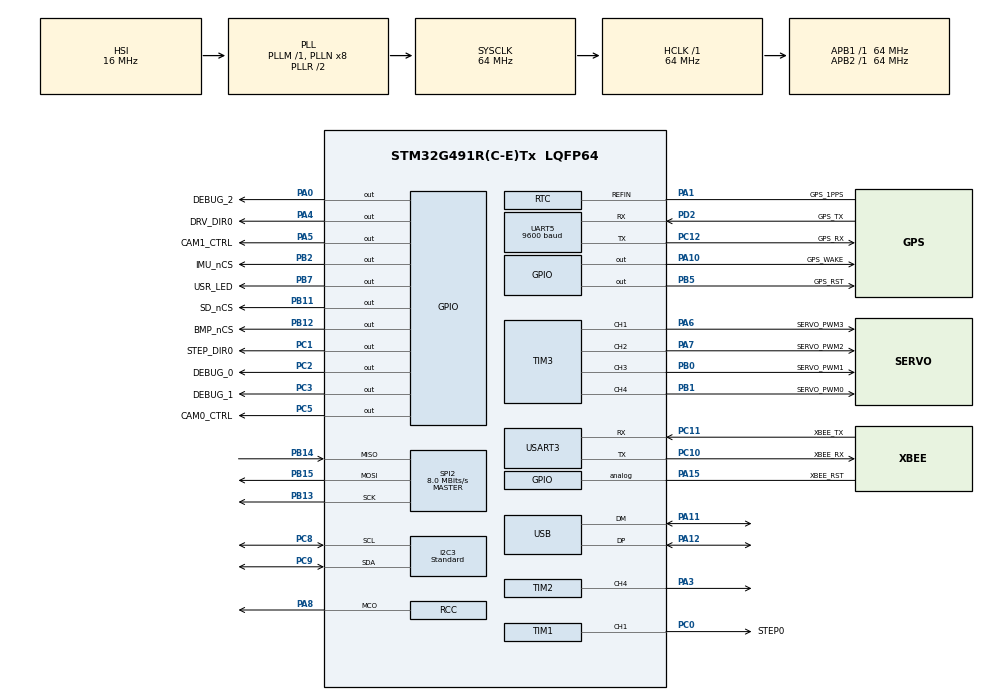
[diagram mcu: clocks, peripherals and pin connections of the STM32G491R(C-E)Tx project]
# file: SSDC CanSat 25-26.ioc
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ADC1.Channel-0\#ChannelRegularConversion=ADC_CHANNEL_VBAT
ADC1.NbrOfConversionFlag=1
ADC1.OffsetNumber-0\#ChannelRegularConversion=ADC_OFFSET_NONE
ADC1.Rank-0\#ChannelRegularConversion=1
ADC1.SamplingTime-0\#ChannelRegularConversion=ADC_SAMPLETIME_2CYCLES_5
ADC1.master=1
Dma.Request0=UART5_RX
Dma.Request1=USART3_RX
Dma.UART5_RX.0.Direction=DMA_PERIPH_TO_MEMORY
Dma.UART5_RX.0.EventEnable=DISABLE
Dma.UART5_RX.0.Instance=DMA1_Channel1
Dma.UART5_RX.0.MemDataAlignment=DMA_MDATAALIGN_BYTE
Dma.UART5_RX.0.MemInc=DMA_MINC_ENABLE
Dma.UART5_RX.0.Mode=DMA_NORMAL
Dma.UART5_RX.0.PeriphDataAlignment=DMA_PDATAALIGN_BYTE
Dma.UART5_RX.0.PeriphInc=DMA_PINC_DISABLE
Dma.UART5_RX.0.Polarity=HAL_DMAMUX_REQ_GEN_RISING
Dma.UART5_RX.0.Priority=DMA_PRIORITY_VERY_HIGH
Dma.UART5_RX.0.RequestNumber=1
Dma.UART5_RX.0.SignalID=NONE
Dma.UART5_RX.0.SyncEnable=DISABLE
Dma.UART5_RX.0.SyncPolarity=HAL_DMAMUX_SYNC_NO_EVENT
Dma.UART5_RX.0.SyncRequestNumber=1
Dma.UART5_RX.0.SyncSignalID=NONE
Dma.USART3_RX.1.Direction=DMA_PERIPH_TO_MEMORY
Dma.USART3_RX.1.EventEnable=DISABLE
Dma.USART3_RX.1.Instance=DMA1_Channel2
Dma.USART3_RX.1.MemDataAlignment=DMA_MDATAALIGN_BYTE
Dma.USART3_RX.1.MemInc=DMA_MINC_ENABLE
Dma.USART3_RX.1.Mode=DMA_NORMAL
Dma.USART3_RX.1.PeriphDataAlignment=DMA_PDATAALIGN_BYTE
Dma.USART3_RX.1.PeriphInc=DMA_PINC_DISABLE
Dma.USART3_RX.1.Polarity=HAL_DMAMUX_REQ_GEN_RISING
Dma.USART3_RX.1.Priority=DMA_PRIORITY_VERY_HIGH
Dma.USART3_RX.1.RequestNumber=1
Dma.USART3_RX.1.SignalID=NONE
Dma.USART3_RX.1.SyncEnable=DISABLE
Dma.USART3_RX.1.SyncPolarity=HAL_DMAMUX_SYNC_NO_EVENT
Dma.USART3_RX.1.SyncRequestNumber=1
Dma.USART3_RX.1.SyncSignalID=NONE
FATFS._FS_LOCK=1
FATFS._FS_REENTRANT=0
FATFS._USE_LFN=0
FATFS._USE_MUTEX=1
FREERTOS.BinarySemaphores01=globalData,Dynamic,NULL,Available
FREERTOS.Tasks01=readSensors,0,600,StartReadSensors,Default,NULL,Dynamic,NULL,NULL;readCommands,0,600,StartReadCommands,Default,NULL,Dynamic,NULL,NULL;sendTelemetry,0,600,StartSendTelemetry,Default,NULL,Dynamic,NULL,NULL;guideNavCtrl,0,600,StartGNC,Default,NULL,Dynamic,NULL,NULL;Init,3,512,StartInit,Default,NULL,Dynamic,NULL,NULL
FREERTOS.configMINIMAL_STACK_SIZE=256
FREERTOS.configTOTAL_HEAP_SIZE=18000
FREERTOS.configUSE_NEWLIB_REENTRANT=1
I2C3.CustomTiming=Disabled
I2C3.I2C_Rise_Time=100
I2C3.I2C_Speed_Mode=I2C_Standard
I2C3.Timing=0x10B17DB5
Mcu.Family=STM32G4
Mcu.Name=STM32G491R(C-E)Tx
Mcu.Package=LQFP64
NVIC.DMA1_Channel1_IRQn=true\:5\:0\:false\:false\:true\:true\:false\:true\:true
NVIC.DMA1_Channel2_IRQn=true\:5\:0\:false\:false\:true\:true\:false\:true\:true
NVIC.PriorityGroup=NVIC_PRIORITYGROUP_4
NVIC.TIM1_UP_TIM16_IRQn=true\:5\:0\:false\:false\:true\:true\:false\:true\:true
NVIC.TIM6_DAC_IRQn=true\:15\:0\:false\:false\:true\:false\:false\:true\:true
NVIC.TimeBase=TIM6_DAC_IRQn
NVIC.TimeBaseIP=TIM6
NVIC.USART3_IRQn=true\:14\:0\:true\:false\:true\:true\:true\:true\:true
NVIC.USB_LP_IRQn=true\:5\:0\:false\:false\:true\:true\:false\:true\:true
PA0.GPIO_Label=DEBUG_2
PA0.Signal=GPIO_Output
PA1.GPIO_Label=GPS_1PPS
PA1.Mode=Reference_Clock_Detection_Activate
PA1.Signal=RTC_REFIN
PA10.GPIO_Label=GPS_WAKE
PA10.Signal=GPIO_Output
PA11.Mode=Device
PA11.Signal=USB_DM
PA12.Mode=Device
PA12.Signal=USB_DP
PA13.GPIO_Label=SWDIO
PA13.Mode=Trace_Asynchronous_SW
PA13.Signal=SYS_JTMS-SWDIO
PA14.GPIO_Label=SWCLK
PA14.Mode=Trace_Asynchronous_SW
PA14.Signal=SYS_JTCK-SWCLK
PA15.GPIO_Label=XBEE_RST
PA15.Signal=GPIO_Analog
PA2.GPIO_Label=CLK_32k
PA2.Mode=Clock-out-LSCO
PA2.Signal=RCC_LSCO
PA3.Signal=S_TIM2_CH4
PA4.GPIO_Label=DRV_DIR0
PA4.Signal=GPIO_Output
PA5.GPIO_Label=CAM1_CTRL
PA5.Signal=GPIO_Output
PA6.GPIO_Label=SERVO_PWM3
PA6.Signal=S_TIM3_CH1
PA7.GPIO_Label=SERVO_PWM2
PA7.Signal=S_TIM3_CH2
PA8.Mode=Clock-out
PA8.Signal=RCC_MCO
PB0.GPIO_Label=SERVO_PWM1
PB0.Signal=S_TIM3_CH3
PB1.GPIO_Label=SERVO_PWM0
PB1.Signal=S_TIM3_CH4
PB11.GPIO_Label=SD_nCS
PB11.Signal=GPIO_Output
PB12.GPIO_Label=BMP_nCS
PB12.Signal=GPIO_Output
PB13.Mode=Full_Duplex_Master
PB13.Signal=SPI2_SCK
PB14.Mode=Full_Duplex_Master
PB14.Signal=SPI2_MISO
PB15.Mode=Full_Duplex_Master
PB15.Signal=SPI2_MOSI
PB2.GPIO_Label=IMU_nCS
PB2.Signal=GPIO_Output
PB3.GPIO_Label=SWO
PB3.Mode=Trace_Asynchronous_SW
PB3.Signal=SYS_JTDO-SWO
PB5.GPIO_Label=GPS_RST
PB5.Signal=GPIO_Output
PB7.GPIO_Label=USR_LED
PB7.Signal=GPIO_Output
PC0.GPIO_Label=STEP0
PC0.Signal=S_TIM1_CH1
PC1.GPIO_Label=STEP_DIR0
PC1.Signal=GPIO_Output
PC10.GPIO_Label=XBEE_RX
PC10.Mode=Asynchronous
PC10.Signal=USART3_TX
PC11.GPIO_Label=XBEE_TX
PC11.Mode=Asynchronous
PC11.Signal=USART3_RX
PC12.GPIO_Label=GPS_RX
PC12.Mode=Asynchronous
PC12.Signal=UART5_TX
PC14-OSC32_IN.GPIO_Label=OSC32_IN
PC14-OSC32_IN.Mode=LSE-External-Oscillator
PC14-OSC32_IN.Signal=RCC_OSC32_IN
PC15-OSC32_OUT.GPIO_Label=OSC32_OUT
PC15-OSC32_OUT.Mode=LSE-External-Oscillator
PC15-OSC32_OUT.Signal=RCC_OSC32_OUT
PC2.GPIO_Label=DEBUG_0
PC2.Signal=GPIO_Output
PC3.GPIO_Label=DEBUG_1
PC3.Signal=GPIO_Output
PC5.GPIO_Label=CAM0_CTRL
PC5.Signal=GPIO_Output
PC8.Mode=I2C
PC8.Signal=I2C3_SCL
PC9.Mode=I2C
PC9.Signal=I2C3_SDA
PD2.GPIO_Label=GPS_TX
PD2.Mode=Asynchronous
PD2.Signal=UART5_RX
ProjectManager.HeapSize=0x400
ProjectManager.StackSize=0x800
ProjectManager.TargetToolchain=STM32CubeIDE
RCC.ADC12Freq_Value=64000000
RCC.ADC345Freq_Value=64000000
RCC.AHBFreq_Value=64000000
RCC.APB1Freq_Value=64000000
RCC.APB1TimFreq_Value=64000000
RCC.APB2Freq_Value=64000000
RCC.APB2TimFreq_Value=64000000
RCC.CortexFreq_Value=64000000
RCC.EXTERNAL_CLOCK_VALUE=12288000
RCC.HCLKFreq_Value=64000000
RCC.HSE_VALUE=8000000
RCC.HSI48_VALUE=48000000
RCC.HSI_VALUE=16000000
RCC.LSCOSource1=RCC_LSCOSOURCE_LSE
RCC.SYSCLKFreq_VALUE=64000000
RCC.SYSCLKSource=RCC_SYSCLKSOURCE_PLLCLK
RCC.VCOOutputFreq_Value=128000000
SH.S_TIM1_CH1.0=TIM1_CH1,PWM Generation1 CH1
SH.S_TIM2_CH4.0=TIM2_CH4,PWM Generation4 CH4
SH.S_TIM3_CH1.0=TIM3_CH1,PWM Generation1 CH1
SH.S_TIM3_CH2.0=TIM3_CH2,PWM Generation2 CH2
SH.S_TIM3_CH3.0=TIM3_CH3,PWM Generation3 CH3
SH.S_TIM3_CH4.0=TIM3_CH4,PWM Generation4 CH4
SPI2.BaudRatePrescaler=SPI_BAUDRATEPRESCALER_8
SPI2.CLKPhase=SPI_PHASE_2EDGE
SPI2.CLKPolarity=SPI_POLARITY_HIGH
SPI2.CalculateBaudRate=8.0 MBits/s
SPI2.DataSize=SPI_DATASIZE_8BIT
SPI2.Direction=SPI_DIRECTION_2LINES
SPI2.Mode=SPI_MODE_MASTER
SPI2.VirtualType=VM_MASTER
TIM1.Channel-PWM\ Generation1\ CH1=TIM_CHANNEL_1
TIM16.Channel=TIM_CHANNEL_1
TIM17.Channel=TIM_CHANNEL_1
TIM2.Channel-PWM\ Generation4\ CH4=TIM_CHANNEL_4
TIM3.Channel-PWM\ Generation3\ CH3=TIM_CHANNEL_3
TIM3.Channel-PWM\ Generation4\ CH4=TIM_CHANNEL_4
UART5.BaudRate=9600
USART3.VirtualMode-Asynchronous=VM_ASYNC
USB_DEVICE.CLASS_NAME_FS=DFU
USB_DEVICE.VirtualMode=Dfu
USB_DEVICE.VirtualModeFS=Dfu_FS
VP_ADC1_TempSens_Input.Mode=IN-TempSens
VP_ADC1_Vbat_Input.Mode=IN-Vbat
VP_ADC1_Vref_Input.Mode=IN-Vrefint
VP_CORDIC_VS_CORDIC.Mode=CORDIC_Activate
VP_FATFS_VS_Generic.Mode=User_defined
VP_FMAC_VS_FMAC.Mode=FMAC_Activate
VP_FREERTOS_VS_CMSIS_V1.Mode=CMSIS_V1
VP_RCC_VS_LSE.Mode=CRS SYNC Source LSE
VP_RNG_VS_RNG.Mode=RNG_Activate
VP_RTC_VS_RTC_Activate.Mode=RTC_Enabled
VP_SYS_VS_DBSignals.Mode=DisableDeadBatterySignals
VP_SYS_VS_tim6.Mode=TIM6
VP_SYS_V_PVD_IN.Mode=Mode_PVD_Int
VP_SYS_V_VREFBUF.Mode=ExternalMode
VP_TIM16_VS_ClockSourceINT.Mode=Enable_Timer
VP_TIM16_VS_no_output1.Mode=PWM Generation1 No Output
VP_TIM17_VS_ClockSourceINT.Mode=Enable_Timer
VP_TIM17_VS_no_output1.Mode=PWM Generation1 No Output
VP_TIM1_VS_ClockSourceINT.Mode=Internal
VP_TIM2_VS_ClockSourceINT.Mode=Internal
VP_TIM3_VS_ClockSourceINT.Mode=Internal
VP_USB_DEVICE_VS_USB_DEVICE_DFU_FS.Mode=DFU_FS
board=custom

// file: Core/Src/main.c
/* USER CODE BEGIN Header */
/**
 ******************************************************************************
 * @file           : main.c
 * @brief          : Main program body
 ******************************************************************************
 * @attention
 *
 * Copyright (c) 2025 STMicroelectronics.
 * All rights reserved.
 *
 * This software is licensed under terms that can be found in the LICENSE file
 * in the root directory of this software component.
 * If no LICENSE file comes with this software, it is provided AS-IS.
 *
 ******************************************************************************
 */
/* USER CODE END Header */
#include "main.h"
#include "cmsis_os.h"
#include "app_fatfs.h"
#include "usb_device.h"

/* USER CODE BEGIN Includes */
#include "../Inc/config.h"
#include "../Inc/global.h"
#include "../Inc/xbee.h"
#include "../Inc/microSD.h"
#include "../Inc/FreeRTOSConfig.h"
#include "../../Drivers/MS5607/MS5607SPI.h"       // Pressure and Temperature Sensor
#include "../../Drivers/ICM42688P/ICM42688PSPI.h" // Accelerometer and Gyro Sensor
#include "../../Drivers/BQ28Z610/BQ28Z610I2C.h"   // Voltage and Current
#include "../../Drivers/STUSB4500LBJR/USB_port.h" // USB PD controller
#include "../../Drivers/TeseoLIV3F/LIV3F.h"         // GPS Module
#include "../../Drivers/SERVO/SERVO.h"      // Servos
#include "../../Middlewares/Third_Party/FreeRTOS/Source/include/task.h"
#include "../Inc/GNC.h"
/* USER CODE END Includes */

/* USER CODE BEGIN PD */

#define BUFFER_SIZE 		256
#define XBEE_MAX_PAYLOAD 	80   // Safe value

#define SERVO_Motor0 4
#define SERVO_Motor1 3
#define SERVO_Motor2 2
#define SERVO_Motor3 1
#define SERVO_Motor4 0

#define EGG_SERVO 		SERVO_Motor0
#define RELEASE_SERVO0 	SERVO_Motor4
#define RELEASE_SERVO1 	SERVO_Motor2
#define GUIDE_SERVO0	SERVO_Motor3
#define GUIDE_SERVO1	SERVO_Motor1
/* USER CODE END PD */

ADC_HandleTypeDef hadc1;

CORDIC_HandleTypeDef hcordic;

FMAC_HandleTypeDef hfmac;

I2C_HandleTypeDef hi2c3;

RNG_HandleTypeDef hrng;

RTC_HandleTypeDef hrtc;

SPI_HandleTypeDef hspi2;

TIM_HandleTypeDef htim1;
TIM_HandleTypeDef htim2;
TIM_HandleTypeDef htim3;
TIM_HandleTypeDef htim16;
TIM_HandleTypeDef htim17;

UART_HandleTypeDef huart5;
UART_HandleTypeDef huart3;
DMA_HandleTypeDef hdma_uart5_rx;
DMA_HandleTypeDef hdma_usart3_rx;

osThreadId readSensorsHandle;
osThreadId readCommandsHandle;
osThreadId sendTelemetryHandle;
osThreadId guideNavCtrlHandle;
osThreadId InitHandle;
osSemaphoreId globalDataHandle;
/* USER CODE BEGIN PV */

uint16_t Timer1, Timer2;
uint8_t gps_dma_buffer[BUFFER_SIZE]   = { 0 };
uint8_t xbee_dma_buffer[BUFFER_SIZE]  = { 0 };
char gps_receive_buffer[BUFFER_SIZE]  = { 0 };
char xbee_receive_buffer[BUFFER_SIZE]  = { 0 };

// At what tick was the last HAL reset.
// Used when we call to update the time.
volatile uint32_t HAL_TICK_OFFSET = 0; // Set when ST is called.

// Flags for GPS and XBEE since they use UART DMA
volatile uint16_t GPS_SIZE 	   		= 0;
volatile uint8_t GPS_READY 	   		= 0;
volatile uint16_t COMMAND_SIZE 		= 0;
volatile uint8_t COMMAND_READY 		= 0;
volatile uint8_t GPS_TIME_ENABLE 	= 0;

GGA_Data_t 		gga_data;
RMC_Data_t 		rmc_data;
PSTMPV_Data_t 	pstmpv_data;

ICM42688P_AccelData ICM42688P_Data = {0};

// GNC Private Variables (PV)
Nav nav 		= {0}; // Initialized in readCommands.
Guidance guid 	= {0}; // no guidance initially, can set this to zero
AutoPilot ap 	= {0}; // same story with the autopilot, can set this to zero
volatile uint8_t CALIBRATE_HEAD_NEEDED = 1;

/* USER CODE END PV */

void SystemClock_Config(void);
static void MX_GPIO_Init(void);
static void MX_DMA_Init(void);
static void MX_RTC_Init(void);
static void MX_SPI2_Init(void);
static void MX_ADC1_Init(void);
static void MX_CORDIC_Init(void);
static void MX_FMAC_Init(void);
static void MX_I2C3_Init(void);
static void MX_RNG_Init(void);
static void MX_UART5_Init(void);
static void MX_USART3_UART_Init(void);
static void MX_TIM3_Init(void);
static void MX_TIM16_Init(void);
static void MX_TIM17_Init(void);
static void MX_TIM1_Init(void);
static void MX_TIM2_Init(void);
void StartReadSensors(void const * argument);
void StartReadCommands(void const * argument);
void StartSendTelemetry(void const * argument);
void StartGNC(void const * argument);
void StartInit(void const * argument);

/* USER CODE BEGIN 0 */

void HAL_UARTEx_RxEventCallback(UART_HandleTypeDef *huart, uint16_t size)
{
  if (huart->Instance == UART5)
  {
    if (!GPS_READY)
    {
		memcpy(gps_receive_buffer, gps_dma_buffer, size);
		GPS_SIZE = size;
		GPS_READY = 1;
		memset(gps_dma_buffer, 0, size);
    }

    if (__HAL_UART_GET_FLAG(&huart5, UART_FLAG_ORE)) {
      __HAL_UART_CLEAR_FLAG(&huart5, UART_CLEAR_OREF);
    }

    HAL_UARTEx_ReceiveToIdle_DMA(huart, gps_dma_buffer, BUFFER_SIZE);
    __HAL_DMA_DISABLE_IT(huart->hdmarx, DMA_IT_HT);
  }

  else if (huart->Instance == USART3)
  {
    if (!COMMAND_READY)
    {
    	memcpy(xbee_receive_buffer, xbee_dma_buffer, size);
    	COMMAND_SIZE = size;
		COMMAND_READY = 1;
		memset(xbee_dma_buffer, 0, size);

    }

    if (__HAL_UART_GET_FLAG(&huart3, UART_FLAG_ORE)) {
    	__HAL_UART_CLEAR_FLAG(&huart3, UART_CLEAR_OREF);
    }

    HAL_UARTEx_ReceiveToIdle_DMA(huart, xbee_dma_buffer, sizeof(xbee_dma_buffer));
    __HAL_DMA_DISABLE_IT(huart->hdmarx, DMA_IT_HT);
  }
  else
  {
    // FIXME : Change this for a DBG LED in the new code
	  HAL_GPIO_TogglePin(DEBUG_1_GPIO_Port, DEBUG_1_Pin);
  }
}

void HAL_UARTEx_ErrorCallback(UART_HandleTypeDef *huart) {
	while(1) {
		// 1 quick 2 slow to show a UART error
		// HAL_GPIO_WritePin(DEBUG_0_GPIO_Port, DEBUG_0_Pin, GPIO_PIN_RESET);
		HAL_Delay(100);
		// HAL_GPIO_WritePin(DEBUG_0_GPIO_Port, DEBUG_0_Pin, GPIO_PIN_RESET);
		HAL_Delay(100);
		// HAL_GPIO_WritePin(DEBUG_0_GPIO_Port, DEBUG_0_Pin, GPIO_PIN_RESET);
		HAL_Delay(200);
		// HAL_GPIO_WritePin(DEBUG_0_GPIO_Port, DEBUG_0_Pin, GPIO_PIN_RESET);
		HAL_Delay(200);
		// HAL_GPIO_WritePin(DEBUG_0_GPIO_Port, DEBUG_0_Pin, GPIO_PIN_RESET);
		HAL_Delay(200);
		// HAL_GPIO_WritePin(DEBUG_0_GPIO_Port, DEBUG_0_Pin, GPIO_PIN_RESET);
		HAL_Delay(200);
	}
}

/* USER CODE END 0 */

int main(void)
{

  /* MCU Configuration--------------------------------------------------------*/

  /* Reset of all peripherals, Initializes the Flash interface and the Systick. */
  HAL_Init();

  /* Configure the system clock */
  SystemClock_Config();

  /* Initialize all configured peripherals */
  MX_GPIO_Init();
  MX_DMA_Init();
  MX_RTC_Init();
  MX_SPI2_Init();
  MX_ADC1_Init();
  MX_CORDIC_Init();
  MX_FMAC_Init();
  MX_I2C3_Init();
  MX_RNG_Init();
  MX_UART5_Init();
  MX_USART3_UART_Init();
  MX_TIM3_Init();
  MX_TIM16_Init();
  MX_TIM17_Init();
  if (MX_FATFS_Init() != APP_OK) {
    Error_Handler();
  }
  MX_TIM1_Init();
  MX_TIM2_Init();
  /* USER CODE BEGIN 2 */

  init_mission_data();
  // Disable ALL chip selects
  HAL_GPIO_WritePin(IMU_nCS_GPIO_Port, IMU_nCS_Pin, GPIO_PIN_SET);
  HAL_GPIO_WritePin(BMP_nCS_GPIO_Port, BMP_nCS_Pin, GPIO_PIN_SET);
  HAL_GPIO_WritePin(SD_nCS_GPIO_Port, SD_nCS_Pin, GPIO_PIN_SET);

  // Hold GPS in reset (LOW)
  HAL_GPIO_WritePin(GPS_RST_GPIO_Port, GPS_RST_Pin, GPIO_PIN_RESET);
  HAL_Delay(100);

  // Fully reset UART5 peripheral
  __HAL_RCC_UART5_FORCE_RESET();
  __HAL_RCC_UART5_RELEASE_RESET();
  MX_UART5_Init();   // reinitialize UART

  // Clear all flags
  __HAL_UART_CLEAR_OREFLAG(&huart5);
  __HAL_UART_CLEAR_FEFLAG(&huart5);
  __HAL_UART_CLEAR_NEFLAG(&huart5);
  __HAL_UART_CLEAR_PEFLAG(&huart5);

  // Fully reset UART3 peripheral
  __HAL_RCC_USART3_FORCE_RESET();
  __HAL_RCC_USART3_RELEASE_RESET();
  MX_USART3_UART_Init();   // reinitialize UART

  // Clear all flags
  __HAL_UART_CLEAR_OREFLAG(&huart3);
  __HAL_UART_CLEAR_FEFLAG(&huart3);
  __HAL_UART_CLEAR_NEFLAG(&huart3);
  __HAL_UART_CLEAR_PEFLAG(&huart3);

  // Now release GPS reset
  HAL_GPIO_WritePin(GPS_RST_GPIO_Port, GPS_RST_Pin, GPIO_PIN_SET);
  HAL_Delay(5000);

  teseo_INIT(&huart5);

  HAL_GPIO_WritePin(XBEE_RST_GPIO_Port, XBEE_RST_Pin, GPIO_PIN_SET);

  // Initalize the tempearture and pressure sensor (MS5607)
  MS5607_Init(&hspi2, BMP_nCS_GPIO_Port, BMP_nCS_Pin);

  ICM42688P_init(&hspi2, IMU_nCS_GPIO_Port, IMU_nCS_Pin);

  // Enable DMA call backs
  // UART 5
  // Check if ORE flag is set, which can happen if data is present on UART RX line
  if (__HAL_UART_GET_FLAG(&huart5, UART_FLAG_ORE)) {
    __HAL_UART_CLEAR_FLAG(&huart5, UART_CLEAR_OREF);
  }
  // receive until idle, then trigger interrupt
  HAL_UARTEx_ReceiveToIdle_DMA(&huart5, gps_dma_buffer, BUFFER_SIZE); // receive until idle, then trigger interrupt
  __HAL_DMA_DISABLE_IT(huart5.hdmarx, DMA_IT_HT); // Disables "Half Transfer" interrupt

  // USART 3
  // Check if ORE flag is set, which can happen if data is present on UART RX line
  if (__HAL_UART_GET_FLAG(&huart3, UART_FLAG_ORE)) {
    __HAL_UART_CLEAR_FLAG(&huart3, UART_CLEAR_OREF);
  }
  // receive until idle, then trigger interrupt
  HAL_UARTEx_ReceiveToIdle_DMA(&huart3, xbee_dma_buffer, sizeof(xbee_dma_buffer)); // receive until idle, then trigger interrupt
  __HAL_DMA_DISABLE_IT(huart3.hdmarx, DMA_IT_HT); // Disables "Half Transfer" interrupt

  /* USER CODE END 2 */

  /* Create the semaphores(s) */
  /* definition and creation of globalData */
  osSemaphoreDef(globalData);
  globalDataHandle = osSemaphoreCreate(osSemaphore(globalData), 1);

  /* Create the thread(s) */
  /* definition and creation of readSensors */
  osThreadDef(readSensors, StartReadSensors, osPriorityNormal, 0, 600);
  readSensorsHandle = osThreadCreate(osThread(readSensors), NULL);

  /* definition and creation of readCommands */
  osThreadDef(readCommands, StartReadCommands, osPriorityNormal, 0, 600);
  readCommandsHandle = osThreadCreate(osThread(readCommands), NULL);

  /* definition and creation of sendTelemetry */
  osThreadDef(sendTelemetry, StartSendTelemetry, osPriorityNormal, 0, 600);
  sendTelemetryHandle = osThreadCreate(osThread(sendTelemetry), NULL);

  /* definition and creation of guideNavCtrl */
  osThreadDef(guideNavCtrl, StartGNC, osPriorityNormal, 0, 600);
  guideNavCtrlHandle = osThreadCreate(osThread(guideNavCtrl), NULL);

  /* definition and creation of Init */
  osThreadDef(Init, StartInit, osPriorityRealtime, 0, 512);
  InitHandle = osThreadCreate(osThread(Init), NULL);

  /* Start scheduler */
  osKernelStart();

  /* We should never get here as control is now taken by the scheduler */

  /* Infinite loop */
  while (1)
  {

  }
}

void SystemClock_Config(void)
{
  RCC_OscInitTypeDef RCC_OscInitStruct = {0};
  RCC_ClkInitTypeDef RCC_ClkInitStruct = {0};
  RCC_CRSInitTypeDef pInit = {0};

  /** Configure the main internal regulator output voltage
  */
  HAL_PWREx_ControlVoltageScaling(PWR_REGULATOR_VOLTAGE_SCALE1);

  /** Configure LSE Drive Capability
  */
  HAL_PWR_EnableBkUpAccess();
  __HAL_RCC_LSEDRIVE_CONFIG(RCC_LSEDRIVE_LOW);

  /** Initializes the RCC Oscillators according to the specified parameters
  * in the RCC_OscInitTypeDef structure.
  */
  RCC_OscInitStruct.OscillatorType = RCC_OSCILLATORTYPE_HSI|RCC_OSCILLATORTYPE_HSI48
                              |RCC_OSCILLATORTYPE_LSI|RCC_OSCILLATORTYPE_LSE;
  RCC_OscInitStruct.LSEState = RCC_LSE_ON;
  RCC_OscInitStruct.HSIState = RCC_HSI_ON;
  RCC_OscInitStruct.HSICalibrationValue = RCC_HSICALIBRATION_DEFAULT;
  RCC_OscInitStruct.LSIState = RCC_LSI_ON;
  RCC_OscInitStruct.HSI48State = RCC_HSI48_ON;
  RCC_OscInitStruct.PLL.PLLState = RCC_PLL_ON;
  RCC_OscInitStruct.PLL.PLLSource = RCC_PLLSOURCE_HSI;
  RCC_OscInitStruct.PLL.PLLM = RCC_PLLM_DIV1;
  RCC_OscInitStruct.PLL.PLLN = 8;
  RCC_OscInitStruct.PLL.PLLP = RCC_PLLP_DIV2;
  RCC_OscInitStruct.PLL.PLLQ = RCC_PLLQ_DIV2;
  RCC_OscInitStruct.PLL.PLLR = RCC_PLLR_DIV2;
  if (HAL_RCC_OscConfig(&RCC_OscInitStruct) != HAL_OK)
  {
    Error_Handler();
  }

  /** Initializes the CPU, AHB and APB buses clocks
  */
  RCC_ClkInitStruct.ClockType = RCC_CLOCKTYPE_HCLK|RCC_CLOCKTYPE_SYSCLK
                              |RCC_CLOCKTYPE_PCLK1|RCC_CLOCKTYPE_PCLK2;
  RCC_ClkInitStruct.SYSCLKSource = RCC_SYSCLKSOURCE_PLLCLK;
  RCC_ClkInitStruct.AHBCLKDivider = RCC_SYSCLK_DIV1;
  RCC_ClkInitStruct.APB1CLKDivider = RCC_HCLK_DIV1;
  RCC_ClkInitStruct.APB2CLKDivider = RCC_HCLK_DIV1;

  if (HAL_RCC_ClockConfig(&RCC_ClkInitStruct, FLASH_LATENCY_2) != HAL_OK)
  {
    Error_Handler();
  }
  HAL_RCC_MCOConfig(RCC_MCO1, RCC_MCO1SOURCE_HSI, RCC_MCODIV_1);
  HAL_RCCEx_EnableLSCO(RCC_LSCOSOURCE_LSE);

  /** Enable the SYSCFG APB clock
  */
  __HAL_RCC_CRS_CLK_ENABLE();

  /** Configures CRS
  */
  pInit.Prescaler = RCC_CRS_SYNC_DIV1;
  pInit.Source = RCC_CRS_SYNC_SOURCE_LSE;
  pInit.Polarity = RCC_CRS_SYNC_POLARITY_RISING;
  pInit.ReloadValue = __HAL_RCC_CRS_RELOADVALUE_CALCULATE(48000000,32768);
  pInit.ErrorLimitValue = 34;
  pInit.HSI48CalibrationValue = 32;

  HAL_RCCEx_CRSConfig(&pInit);
}

static void MX_ADC1_Init(void)
{

  ADC_MultiModeTypeDef multimode = {0};
  ADC_ChannelConfTypeDef sConfig = {0};

  /** Common config
  */
  hadc1.Instance = ADC1;
  hadc1.Init.ClockPrescaler = ADC_CLOCK_SYNC_PCLK_DIV2;
  hadc1.Init.Resolution = ADC_RESOLUTION_12B;
  hadc1.Init.DataAlign = ADC_DATAALIGN_RIGHT;
  hadc1.Init.GainCompensation = 0;
  hadc1.Init.ScanConvMode = ADC_SCAN_DISABLE;
  hadc1.Init.EOCSelection = ADC_EOC_SINGLE_CONV;
  hadc1.Init.LowPowerAutoWait = DISABLE;
  hadc1.Init.ContinuousConvMode = DISABLE;
  hadc1.Init.NbrOfConversion = 1;
  hadc1.Init.DiscontinuousConvMode = DISABLE;
  hadc1.Init.ExternalTrigConv = ADC_SOFTWARE_START;
  hadc1.Init.ExternalTrigConvEdge = ADC_EXTERNALTRIGCONVEDGE_NONE;
  hadc1.Init.DMAContinuousRequests = DISABLE;
  hadc1.Init.Overrun = ADC_OVR_DATA_PRESERVED;
  hadc1.Init.OversamplingMode = DISABLE;
  if (HAL_ADC_Init(&hadc1) != HAL_OK)
  {
    Error_Handler();
  }

  /** Configure the ADC multi-mode
  */
  multimode.Mode = ADC_MODE_INDEPENDENT;
  if (HAL_ADCEx_MultiModeConfigChannel(&hadc1, &multimode) != HAL_OK)
  {
    Error_Handler();
  }

  /** Configure Regular Channel
  */
  sConfig.Channel = ADC_CHANNEL_VBAT;
  sConfig.Rank = ADC_REGULAR_RANK_1;
  sConfig.SamplingTime = ADC_SAMPLETIME_2CYCLES_5;
  sConfig.SingleDiff = ADC_SINGLE_ENDED;
  sConfig.OffsetNumber = ADC_OFFSET_NONE;
  sConfig.Offset = 0;
  if (HAL_ADC_ConfigChannel(&hadc1, &sConfig) != HAL_OK)
  {
    Error_Handler();
  }

}

static void MX_CORDIC_Init(void)
{

  hcordic.Instance = CORDIC;
  if (HAL_CORDIC_Init(&hcordic) != HAL_OK)
  {
    Error_Handler();
  }

}

static void MX_FMAC_Init(void)
{

  hfmac.Instance = FMAC;
  if (HAL_FMAC_Init(&hfmac) != HAL_OK)
  {
    Error_Handler();
  }

}

static void MX_I2C3_Init(void)
{

  hi2c3.Instance = I2C3;
  hi2c3.Init.Timing = 0x10B17DB5;
  hi2c3.Init.OwnAddress1 = 0;
  hi2c3.Init.AddressingMode = I2C_ADDRESSINGMODE_7BIT;
  hi2c3.Init.DualAddressMode = I2C_DUALADDRESS_DISABLE;
  hi2c3.Init.OwnAddress2 = 0;
  hi2c3.Init.OwnAddress2Masks = I2C_OA2_NOMASK;
  hi2c3.Init.GeneralCallMode = I2C_GENERALCALL_DISABLE;
  hi2c3.Init.NoStretchMode = I2C_NOSTRETCH_DISABLE;
  if (HAL_I2C_Init(&hi2c3) != HAL_OK)
  {
    Error_Handler();
  }

  /** Configure Analogue filter
  */
  if (HAL_I2CEx_ConfigAnalogFilter(&hi2c3, I2C_ANALOGFILTER_ENABLE) != HAL_OK)
  {
    Error_Handler();
  }

  /** Configure Digital filter
  */
  if (HAL_I2CEx_ConfigDigitalFilter(&hi2c3, 0) != HAL_OK)
  {
    Error_Handler();
  }

}

static void MX_RNG_Init(void)
{

  hrng.Instance = RNG;
  hrng.Init.ClockErrorDetection = RNG_CED_ENABLE;
  if (HAL_RNG_Init(&hrng) != HAL_OK)
  {
    Error_Handler();
  }

}

static void MX_RTC_Init(void)
{

  /** Initialize RTC Only
  */
  hrtc.Instance = RTC;
  hrtc.Init.HourFormat = RTC_HOURFORMAT_24;
  hrtc.Init.AsynchPrediv = 127;
  hrtc.Init.SynchPrediv = 255;
  hrtc.Init.OutPut = RTC_OUTPUT_DISABLE;
  hrtc.Init.OutPutRemap = RTC_OUTPUT_REMAP_NONE;
  hrtc.Init.OutPutPolarity = RTC_OUTPUT_POLARITY_HIGH;
  hrtc.Init.OutPutType = RTC_OUTPUT_TYPE_OPENDRAIN;
  hrtc.Init.OutPutPullUp = RTC_OUTPUT_PULLUP_NONE;
  if (HAL_RTC_Init(&hrtc) != HAL_OK)
  {
    Error_Handler();
  }

  /** Enable the reference Clock input
  */
  if (HAL_RTCEx_SetRefClock(&hrtc) != HAL_OK)
  {
    Error_Handler();
  }

}

static void MX_SPI2_Init(void)
{

  /* SPI2 parameter configuration*/
  hspi2.Instance = SPI2;
  hspi2.Init.Mode = SPI_MODE_MASTER;
  hspi2.Init.Direction = SPI_DIRECTION_2LINES;
  hspi2.Init.DataSize = SPI_DATASIZE_8BIT;
  hspi2.Init.CLKPolarity = SPI_POLARITY_HIGH;
  hspi2.Init.CLKPhase = SPI_PHASE_2EDGE;
  hspi2.Init.NSS = SPI_NSS_SOFT;
  hspi2.Init.BaudRatePrescaler = SPI_BAUDRATEPRESCALER_8;
  hspi2.Init.FirstBit = SPI_FIRSTBIT_MSB;
  hspi2.Init.TIMode = SPI_TIMODE_DISABLE;
  hspi2.Init.CRCCalculation = SPI_CRCCALCULATION_DISABLE;
  hspi2.Init.CRCPolynomial = 7;
  hspi2.Init.CRCLength = SPI_CRC_LENGTH_DATASIZE;
  hspi2.Init.NSSPMode = SPI_NSS_PULSE_DISABLE;
  if (HAL_SPI_Init(&hspi2) != HAL_OK)
  {
    Error_Handler();
  }

}

static void MX_TIM1_Init(void)
{

  TIM_ClockConfigTypeDef sClockSourceConfig = {0};
  TIM_MasterConfigTypeDef sMasterConfig = {0};
  TIM_OC_InitTypeDef sConfigOC = {0};
  TIM_BreakDeadTimeConfigTypeDef sBreakDeadTimeConfig = {0};

  htim1.Instance = TIM1;
  htim1.Init.Prescaler = 0;
  htim1.Init.CounterMode = TIM_COUNTERMODE_UP;
  htim1.Init.Period = 65535;
  htim1.Init.ClockDivision = TIM_CLOCKDIVISION_DIV1;
  htim1.Init.RepetitionCounter = 0;
  htim1.Init.AutoReloadPreload = TIM_AUTORELOAD_PRELOAD_DISABLE;
  if (HAL_TIM_Base_Init(&htim1) != HAL_OK)
  {
    Error_Handler();
  }
  sClockSourceConfig.ClockSource = TIM_CLOCKSOURCE_INTERNAL;
  if (HAL_TIM_ConfigClockSource(&htim1, &sClockSourceConfig) != HAL_OK)
  {
    Error_Handler();
  }
  if (HAL_TIM_PWM_Init(&htim1) != HAL_OK)
  {
    Error_Handler();
  }
  sMasterConfig.MasterOutputTrigger = TIM_TRGO_RESET;
  sMasterConfig.MasterOutputTrigger2 = TIM_TRGO2_RESET;
  sMasterConfig.MasterSlaveMode = TIM_MASTERSLAVEMODE_DISABLE;
  if (HAL_TIMEx_MasterConfigSynchronization(&htim1, &sMasterConfig) != HAL_OK)
  {
    Error_Handler();
  }
  sConfigOC.OCMode = TIM_OCMODE_PWM1;
  sConfigOC.Pulse = 0;
  sConfigOC.OCPolarity = TIM_OCPOLARITY_HIGH;
  sConfigOC.OCNPolarity = TIM_OCNPOLARITY_HIGH;
  sConfigOC.OCFastMode = TIM_OCFAST_DISABLE;
  sConfigOC.OCIdleState = TIM_OCIDLESTATE_RESET;
  sConfigOC.OCNIdleState = TIM_OCNIDLESTATE_RESET;
  if (HAL_TIM_PWM_ConfigChannel(&htim1, &sConfigOC, TIM_CHANNEL_1) != HAL_OK)
  {
    Error_Handler();
  }
  sBreakDeadTimeConfig.OffStateRunMode = TIM_OSSR_DISABLE;
  sBreakDeadTimeConfig.OffStateIDLEMode = TIM_OSSI_DISABLE;
  sBreakDeadTimeConfig.LockLevel = TIM_LOCKLEVEL_OFF;
  sBreakDeadTimeConfig.DeadTime = 0;
  sBreakDeadTimeConfig.BreakState = TIM_BREAK_DISABLE;
  sBreakDeadTimeConfig.BreakPolarity = TIM_BREAKPOLARITY_HIGH;
  sBreakDeadTimeConfig.BreakFilter = 0;
  sBreakDeadTimeConfig.BreakAFMode = TIM_BREAK_AFMODE_INPUT;
  sBreakDeadTimeConfig.Break2State = TIM_BREAK2_DISABLE;
  sBreakDeadTimeConfig.Break2Polarity = TIM_BREAK2POLARITY_HIGH;
  sBreakDeadTimeConfig.Break2Filter = 0;
  sBreakDeadTimeConfig.Break2AFMode = TIM_BREAK_AFMODE_INPUT;
  sBreakDeadTimeConfig.AutomaticOutput = TIM_AUTOMATICOUTPUT_DISABLE;
  if (HAL_TIMEx_ConfigBreakDeadTime(&htim1, &sBreakDeadTimeConfig) != HAL_OK)
  {
    Error_Handler();
  }
  HAL_TIM_MspPostInit(&htim1);

}

static void MX_TIM2_Init(void)
{

  TIM_ClockConfigTypeDef sClockSourceConfig = {0};
  TIM_MasterConfigTypeDef sMasterConfig = {0};
  TIM_OC_InitTypeDef sConfigOC = {0};

  htim2.Instance = TIM2;
  htim2.Init.Prescaler = 0;
  htim2.Init.CounterMode = TIM_COUNTERMODE_UP;
  htim2.Init.Period = 4294967295;
  htim2.Init.ClockDivision = TIM_CLOCKDIVISION_DIV1;
  htim2.Init.AutoReloadPreload = TIM_AUTORELOAD_PRELOAD_DISABLE;
  if (HAL_TIM_Base_Init(&htim2) != HAL_OK)
  {
    Error_Handler();
  }
  sClockSourceConfig.ClockSource = TIM_CLOCKSOURCE_INTERNAL;
  if (HAL_TIM_ConfigClockSource(&htim2, &sClockSourceConfig) != HAL_OK)
  {
    Error_Handler();
  }
  if (HAL_TIM_PWM_Init(&htim2) != HAL_OK)
  {
    Error_Handler();
  }
  sMasterConfig.MasterOutputTrigger = TIM_TRGO_RESET;
  sMasterConfig.MasterSlaveMode = TIM_MASTERSLAVEMODE_DISABLE;
  if (HAL_TIMEx_MasterConfigSynchronization(&htim2, &sMasterConfig) != HAL_OK)
  {
    Error_Handler();
  }
  sConfigOC.OCMode = TIM_OCMODE_PWM1;
  sConfigOC.Pulse = 0;
  sConfigOC.OCPolarity = TIM_OCPOLARITY_HIGH;
  sConfigOC.OCFastMode = TIM_OCFAST_DISABLE;
  if (HAL_TIM_PWM_ConfigChannel(&htim2, &sConfigOC, TIM_CHANNEL_4) != HAL_OK)
  {
    Error_Handler();
  }
  HAL_TIM_MspPostInit(&htim2);

}

static void MX_TIM3_Init(void)
{

  TIM_ClockConfigTypeDef sClockSourceConfig = {0};
  TIM_MasterConfigTypeDef sMasterConfig = {0};
  TIM_OC_InitTypeDef sConfigOC = {0};

  htim3.Instance = TIM3;
  htim3.Init.Prescaler = 0;
  htim3.Init.CounterMode = TIM_COUNTERMODE_UP;
  htim3.Init.Period = 65535;
  htim3.Init.ClockDivision = TIM_CLOCKDIVISION_DIV1;
  htim3.Init.AutoReloadPreload = TIM_AUTORELOAD_PRELOAD_DISABLE;
  if (HAL_TIM_Base_Init(&htim3) != HAL_OK)
  {
    Error_Handler();
  }
  sClockSourceConfig.ClockSource = TIM_CLOCKSOURCE_INTERNAL;
  if (HAL_TIM_ConfigClockSource(&htim3, &sClockSourceConfig) != HAL_OK)
  {
    Error_Handler();
  }
  if (HAL_TIM_PWM_Init(&htim3) != HAL_OK)
  {
    Error_Handler();
  }
  sMasterConfig.MasterOutputTrigger = TIM_TRGO_RESET;
  sMasterConfig.MasterSlaveMode = TIM_MASTERSLAVEMODE_DISABLE;
  if (HAL_TIMEx_MasterConfigSynchronization(&htim3, &sMasterConfig) != HAL_OK)
  {
    Error_Handler();
  }
  sConfigOC.OCMode = TIM_OCMODE_PWM1;
  sConfigOC.Pulse = 0;
  sConfigOC.OCPolarity = TIM_OCPOLARITY_HIGH;
  sConfigOC.OCFastMode = TIM_OCFAST_DISABLE;
  if (HAL_TIM_PWM_ConfigChannel(&htim3, &sConfigOC, TIM_CHANNEL_1) != HAL_OK)
  {
    Error_Handler();
  }
  if (HAL_TIM_PWM_ConfigChannel(&htim3, &sConfigOC, TIM_CHANNEL_2) != HAL_OK)
  {
    Error_Handler();
  }
  if (HAL_TIM_PWM_ConfigChannel(&htim3, &sConfigOC, TIM_CHANNEL_3) != HAL_OK)
  {
    Error_Handler();
  }
  if (HAL_TIM_PWM_ConfigChannel(&htim3, &sConfigOC, TIM_CHANNEL_4) != HAL_OK)
  {
    Error_Handler();
  }
  HAL_TIM_MspPostInit(&htim3);

}

static void MX_TIM16_Init(void)
{

  TIM_OC_InitTypeDef sConfigOC = {0};
  TIM_BreakDeadTimeConfigTypeDef sBreakDeadTimeConfig = {0};

  htim16.Instance = TIM16;
  htim16.Init.Prescaler = 0;
  htim16.Init.CounterMode = TIM_COUNTERMODE_UP;
  htim16.Init.Period = 65535;
  htim16.Init.ClockDivision = TIM_CLOCKDIVISION_DIV1;
  htim16.Init.RepetitionCounter = 0;
  htim16.Init.AutoReloadPreload = TIM_AUTORELOAD_PRELOAD_DISABLE;
  if (HAL_TIM_Base_Init(&htim16) != HAL_OK)
  {
    Error_Handler();
  }
  if (HAL_TIM_PWM_Init(&htim16) != HAL_OK)
  {
    Error_Handler();
  }
  sConfigOC.OCMode = TIM_OCMODE_PWM1;
  sConfigOC.Pulse = 0;
  sConfigOC.OCPolarity = TIM_OCPOLARITY_HIGH;
  sConfigOC.OCNPolarity = TIM_OCNPOLARITY_HIGH;
  sConfigOC.OCFastMode = TIM_OCFAST_DISABLE;
  sConfigOC.OCIdleState = TIM_OCIDLESTATE_RESET;
  sConfigOC.OCNIdleState = TIM_OCNIDLESTATE_RESET;
  if (HAL_TIM_PWM_ConfigChannel(&htim16, &sConfigOC, TIM_CHANNEL_1) != HAL_OK)
  {
    Error_Handler();
  }
  sBreakDeadTimeConfig.OffStateRunMode = TIM_OSSR_DISABLE;
  sBreakDeadTimeConfig.OffStateIDLEMode = TIM_OSSI_DISABLE;
  sBreakDeadTimeConfig.LockLevel = TIM_LOCKLEVEL_OFF;
  sBreakDeadTimeConfig.DeadTime = 0;
  sBreakDeadTimeConfig.BreakState = TIM_BREAK_DISABLE;
  sBreakDeadTimeConfig.BreakPolarity = TIM_BREAKPOLARITY_HIGH;
  sBreakDeadTimeConfig.BreakFilter = 0;
  sBreakDeadTimeConfig.AutomaticOutput = TIM_AUTOMATICOUTPUT_DISABLE;
  if (HAL_TIMEx_ConfigBreakDeadTime(&htim16, &sBreakDeadTimeConfig) != HAL_OK)
  {
    Error_Handler();
  }

}

static void MX_TIM17_Init(void)
{

  TIM_OC_InitTypeDef sConfigOC = {0};
  TIM_BreakDeadTimeConfigTypeDef sBreakDeadTimeConfig = {0};

  htim17.Instance = TIM17;
  htim17.Init.Prescaler = 0;
  htim17.Init.CounterMode = TIM_COUNTERMODE_UP;
  htim17.Init.Period = 65535;
  htim17.Init.ClockDivision = TIM_CLOCKDIVISION_DIV1;
  htim17.Init.RepetitionCounter = 0;
  htim17.Init.AutoReloadPreload = TIM_AUTORELOAD_PRELOAD_DISABLE;
  if (HAL_TIM_Base_Init(&htim17) != HAL_OK)
  {
    Error_Handler();
  }
  if (HAL_TIM_PWM_Init(&htim17) != HAL_OK)
  {
    Error_Handler();
  }
  sConfigOC.OCMode = TIM_OCMODE_PWM1;
  sConfigOC.Pulse = 0;
  sConfigOC.OCPolarity = TIM_OCPOLARITY_HIGH;
  sConfigOC.OCNPolarity = TIM_OCNPOLARITY_HIGH;
  sConfigOC.OCFastMode = TIM_OCFAST_DISABLE;
  sConfigOC.OCIdleState = TIM_OCIDLESTATE_RESET;
  sConfigOC.OCNIdleState = TIM_OCNIDLESTATE_RESET;
  if (HAL_TIM_PWM_ConfigChannel(&htim17, &sConfigOC, TIM_CHANNEL_1) != HAL_OK)
  {
    Error_Handler();
  }
  sBreakDeadTimeConfig.OffStateRunMode = TIM_OSSR_DISABLE;
  sBreakDeadTimeConfig.OffStateIDLEMode = TIM_OSSI_DISABLE;
  sBreakDeadTimeConfig.LockLevel = TIM_LOCKLEVEL_OFF;
  sBreakDeadTimeConfig.DeadTime = 0;
  sBreakDeadTimeConfig.BreakState = TIM_BREAK_DISABLE;
  sBreakDeadTimeConfig.BreakPolarity = TIM_BREAKPOLARITY_HIGH;
  sBreakDeadTimeConfig.BreakFilter = 0;
  sBreakDeadTimeConfig.AutomaticOutput = TIM_AUTOMATICOUTPUT_DISABLE;
  if (HAL_TIMEx_ConfigBreakDeadTime(&htim17, &sBreakDeadTimeConfig) != HAL_OK)
  {
    Error_Handler();
  }

}

static void MX_UART5_Init(void)
{

  huart5.Instance = UART5;
  huart5.Init.BaudRate = 9600;
  huart5.Init.WordLength = UART_WORDLENGTH_8B;
  huart5.Init.StopBits = UART_STOPBITS_1;
  huart5.Init.Parity = UART_PARITY_NONE;
  huart5.Init.Mode = UART_MODE_TX_RX;
  huart5.Init.HwFlowCtl = UART_HWCONTROL_NONE;
  huart5.Init.OverSampling = UART_OVERSAMPLING_16;
  huart5.Init.OneBitSampling = UART_ONE_BIT_SAMPLE_DISABLE;
  huart5.Init.ClockPrescaler = UART_PRESCALER_DIV1;
  huart5.AdvancedInit.AdvFeatureInit = UART_ADVFEATURE_NO_INIT;
  if (HAL_UART_Init(&huart5) != HAL_OK)
  {
    Error_Handler();
  }
  if (HAL_UARTEx_SetTxFifoThreshold(&huart5, UART_TXFIFO_THRESHOLD_1_8) != HAL_OK)
  {
    Error_Handler();
  }
  if (HAL_UARTEx_SetRxFifoThreshold(&huart5, UART_RXFIFO_THRESHOLD_1_8) != HAL_OK)
  {
    Error_Handler();
  }
  if (HAL_UARTEx_DisableFifoMode(&huart5) != HAL_OK)
  {
    Error_Handler();
  }

}

static void MX_USART3_UART_Init(void)
{

  huart3.Instance = USART3;
  huart3.Init.BaudRate = 115200;
  huart3.Init.WordLength = UART_WORDLENGTH_8B;
  huart3.Init.StopBits = UART_STOPBITS_1;
  huart3.Init.Parity = UART_PARITY_NONE;
  huart3.Init.Mode = UART_MODE_TX_RX;
  huart3.Init.HwFlowCtl = UART_HWCONTROL_NONE;
  huart3.Init.OverSampling = UART_OVERSAMPLING_16;
  huart3.Init.OneBitSampling = UART_ONE_BIT_SAMPLE_DISABLE;
  huart3.Init.ClockPrescaler = UART_PRESCALER_DIV1;
  huart3.AdvancedInit.AdvFeatureInit = UART_ADVFEATURE_NO_INIT;
  if (HAL_UART_Init(&huart3) != HAL_OK)
  {
    Error_Handler();
  }
  if (HAL_UARTEx_SetTxFifoThreshold(&huart3, UART_TXFIFO_THRESHOLD_1_8) != HAL_OK)
  {
    Error_Handler();
  }
  if (HAL_UARTEx_SetRxFifoThreshold(&huart3, UART_RXFIFO_THRESHOLD_1_8) != HAL_OK)
  {
    Error_Handler();
  }
  if (HAL_UARTEx_DisableFifoMode(&huart3) != HAL_OK)
  {
    Error_Handler();
  }

}

static void MX_DMA_Init(void)
{

  /* DMA controller clock enable */
  __HAL_RCC_DMAMUX1_CLK_ENABLE();
  __HAL_RCC_DMA1_CLK_ENABLE();

  /* DMA interrupt init */
  /* DMA1_Channel1_IRQn interrupt configuration */
  HAL_NVIC_SetPriority(DMA1_Channel1_IRQn, 5, 0);
  HAL_NVIC_EnableIRQ(DMA1_Channel1_IRQn);
  /* DMA1_Channel2_IRQn interrupt configuration */
  HAL_NVIC_SetPriority(DMA1_Channel2_IRQn, 5, 0);
  HAL_NVIC_EnableIRQ(DMA1_Channel2_IRQn);

}

static void MX_GPIO_Init(void)
{
  GPIO_InitTypeDef GPIO_InitStruct = {0};

  /* GPIO Ports Clock Enable */
  __HAL_RCC_GPIOC_CLK_ENABLE();
  __HAL_RCC_GPIOA_CLK_ENABLE();
  __HAL_RCC_GPIOB_CLK_ENABLE();
  __HAL_RCC_GPIOD_CLK_ENABLE();

  /*Configure GPIO pin Output Level */
  HAL_GPIO_WritePin(GPIOC, STEP_DIR0_Pin|DEBUG_0_Pin|DEBUG_1_Pin|CAM0_CTRL_Pin, GPIO_PIN_RESET);

  /*Configure GPIO pin Output Level */
  HAL_GPIO_WritePin(GPIOA, DEBUG_2_Pin|DRV_DIR0_Pin|CAM1_CTRL_Pin|GPS_WAKE_Pin, GPIO_PIN_RESET);

  /*Configure GPIO pin Output Level */
  HAL_GPIO_WritePin(GPIOB, IMU_nCS_Pin|SD_nCS_Pin|BMP_nCS_Pin|GPS_RST_Pin
                          |USR_LED_Pin, GPIO_PIN_RESET);

  /*Configure GPIO pins : STEP_DIR0_Pin DEBUG_0_Pin DEBUG_1_Pin CAM0_CTRL_Pin */
  GPIO_InitStruct.Pin = STEP_DIR0_Pin|DEBUG_0_Pin|DEBUG_1_Pin|CAM0_CTRL_Pin;
  GPIO_InitStruct.Mode = GPIO_MODE_OUTPUT_PP;
  GPIO_InitStruct.Pull = GPIO_NOPULL;
  GPIO_InitStruct.Speed = GPIO_SPEED_FREQ_LOW;
  HAL_GPIO_Init(GPIOC, &GPIO_InitStruct);

  /*Configure GPIO pins : DEBUG_2_Pin DRV_DIR0_Pin CAM1_CTRL_Pin GPS_WAKE_Pin */
  GPIO_InitStruct.Pin = DEBUG_2_Pin|DRV_DIR0_Pin|CAM1_CTRL_Pin|GPS_WAKE_Pin;
  GPIO_InitStruct.Mode = GPIO_MODE_OUTPUT_PP;
  GPIO_InitStruct.Pull = GPIO_NOPULL;
  GPIO_InitStruct.Speed = GPIO_SPEED_FREQ_LOW;
  HAL_GPIO_Init(GPIOA, &GPIO_InitStruct);

  /*Configure GPIO pins : CLK_32k_Pin XBEE_RST_Pin */
  GPIO_InitStruct.Pin = CLK_32k_Pin|XBEE_RST_Pin;
  GPIO_InitStruct.Mode = GPIO_MODE_ANALOG;
  GPIO_InitStruct.Pull = GPIO_NOPULL;
  HAL_GPIO_Init(GPIOA, &GPIO_InitStruct);

  /*Configure GPIO pins : IMU_nCS_Pin SD_nCS_Pin BMP_nCS_Pin GPS_RST_Pin
                           USR_LED_Pin */
  GPIO_InitStruct.Pin = IMU_nCS_Pin|SD_nCS_Pin|BMP_nCS_Pin|GPS_RST_Pin
                          |USR_LED_Pin;
  GPIO_InitStruct.Mode = GPIO_MODE_OUTPUT_PP;
  GPIO_InitStruct.Pull = GPIO_NOPULL;
  GPIO_InitStruct.Speed = GPIO_SPEED_FREQ_LOW;
  HAL_GPIO_Init(GPIOB, &GPIO_InitStruct);

  /*Configure GPIO pin : PA8 */
  GPIO_InitStruct.Pin = GPIO_PIN_8;
  GPIO_InitStruct.Mode = GPIO_MODE_AF_PP;
  GPIO_InitStruct.Pull = GPIO_NOPULL;
  GPIO_InitStruct.Speed = GPIO_SPEED_FREQ_LOW;
  GPIO_InitStruct.Alternate = GPIO_AF0_MCO;
  HAL_GPIO_Init(GPIOA, &GPIO_InitStruct);

}

/* USER CODE BEGIN 4 */
void vApplicationTickHook(void){
	if(Timer1 > 0)
		Timer1--;
	if(Timer2 > 0)
		Timer2--;
}

// This is a call back in case a thread has a stack overflow.
// pcTaskName is the name of the offending task
void vApplicationStackOverflowHook(TaskHandle_t xTask, char *pcTaskName)
{
    (void)xTask;
    (void)pcTaskName;
    // Forces a breakpoint in the debugger
    __BKPT(0);
    for (;;);
}

// Incase there is an error with a Malloc somewhere
void vApplicationMallocFailedHook(void)
{
    // Fires if pvPortMalloc fails — useful to catch heap exhaustion

	// Forces a breakpoint in the debugger
    __BKPT(0);
    for (;;);
}

/* USER CODE END 4 */

void StartReadSensors(void const * argument)
{
  /* init code for USB_Device */
  MX_USB_Device_Init();
  /* USER CODE BEGIN 5 */
  osStatus stat = osErrorOS;

  char testing_data[200];

  /* Infinite loop */
  for (;;)
  {
	stat = osSemaphoreWait(globalDataHandle, 100);
	if (stat != osOK) {
	  osThreadYield();
	  continue;
	}
    // #1 PRIORITY: make sure mutex unlocks no matter what!!!!

    // -> if a HIGHER priority task attempts to access a locked resource,
    // the LOCKING thread assumes the priority of the resource trying to
    // take it

    /*
     * global_mission_data.MODE, global_mission_data.CMD_ECHO,
     * and global_mission_data.PACKET_COUNT
     * is dealt with in readCommands.
     */

    MS5607Readings MS5607_Data = MS5607ReadValues();
    // TODO : This should probably just use the flag simulation_enable
    if (global_mission_data.MODE == 'F')
    { // In Flight Mode
      global_mission_data.PRESSURE = MS5607_Data.pressure_kPa;
    }
    else
    { // In Simulation Mode
     global_mission_data.PRESSURE = simulated_pressure;
    }

    global_mission_data.TEMPERATURE = MS5607_Data.temperature_C;

    global_mission_data.ALTITUDE = calculateAltitude(global_mission_data.PRESSURE) - global_mission_data.ALTITUDE_OFFSET;

    determineState(&nav);

    // ICM42688P_AccelData ICM42688P_Data = ICM42688P_read_data();
    ICM42688P_read_data(&ICM42688P_Data);
    global_mission_data.GYRO_R = ICM42688P_Data.gyro_r;
    global_mission_data.GYRO_P = ICM42688P_Data.gyro_p;
    global_mission_data.GYRO_Y = ICM42688P_Data.gyro_y;

    global_mission_data.ACCEL_X = ICM42688P_Data.accel_x;
    global_mission_data.ACCEL_Y = ICM42688P_Data.accel_y;
    global_mission_data.ACCEL_Z = ICM42688P_Data.accel_z;

    global_mission_data.ACCEL_R = ICM42688P_Data.accel_r;
    global_mission_data.ACCEL_P = ICM42688P_Data.accel_p;
    global_mission_data.ACCEL_YAW = ICM42688P_Data.accel_yaw;

 //   struct bmm350_mag_temp_data mag_data;
 //   BMM350_read_mag_data(&bmm350, &mag_data);

     uint16_t voltage = 0;
     HAL_StatusTypeDef status = BQ28Z610_ReadVoltage(&hi2c3, &voltage);
     if (status == HAL_OK) {
         global_mission_data.VOLTAGE = (float)voltage / 1000;
     }

     int16_t current = 0;
     status = BQ28Z610_ReadCurrent(&hi2c3, &current);
     if (status == HAL_OK)
     {
     	global_mission_data.CURRENT = (float)current / 1000;
     }

    //New code
    if (GPS_READY)
    {
        // From my understanding: When the DMA interrupt occurs, we will copy the message from the DMA buffer
        // into the gps_receive_buffer. From there, we can then pass the receive buffer with the message into parse_gga
        int result = parse_gps_buffer(gps_receive_buffer, &gga_data, &rmc_data, &pstmpv_data);
        GPS_READY = 0;

        //result is 1 on success
        if (result == 1)
        {
 //           HAL_GPIO_TogglePin(DEBUG_0_GPIO_Port, DEBUG_0_Pin);
            global_mission_data.GPS_LATITUDE = gga_data.latitude;
            global_mission_data.GPS_LONGITUDE = gga_data.longitude;
            global_mission_data.GPS_ALTITUDE = gga_data.altitude;
            global_mission_data.GPS_SATS = gga_data.num_satellites;

            strcpy(global_mission_data.GPS_TIME, gga_data.gps_time);
        }
        else if (result == 2)
        {
     	   global_mission_data.GPS_LATITUDE = rmc_data.latitude;
     	   global_mission_data.GPS_LONGITUDE = rmc_data.longitude;

     	   strcpy(global_mission_data.GPS_TIME, rmc_data.gps_time);
        }
        else
        {
     	   HAL_GPIO_TogglePin(DEBUG_2_GPIO_Port, DEBUG_2_Pin);
        }
    }

    if(calibrating) {

        cal_sum += global_mission_data.PRESSURE;
        cal_count++;

        if(cal_count >= 10) {
            float pressure_avg = cal_sum / cal_count;
            global_mission_data.ALTITUDE_OFFSET = calculateAltitude(pressure_avg);

     	   calibrating = 0;
     	   is_calibrated = 1;
        }

	   // TODO: Initialize nav for GNC.
	   //MAIN INITIALIZATION - run once to initialize Nav struct
	           //1) initialize gyro,accel,mag offsets at launch pad
	           //2) read from sensors and run init_Navigation()
	               //EXAMPLE: Nav nav = init_Navigation(data, gga, PSTMPV, GPS_ready);
	               //Guidance guid = {0}; //can make guidance blank until we enter control loop
	           //3) need something that will start the main loop when glider outside container, can we use descent acceleration?
	               /*
	               The accelerometer, though noisy, should measure nearly +1g when the glider reaches terminal velocity.
	               So we can use a conditional that checks ICM42688P accel_z (or whichever axis is pointing vertical) and
	               see when it's close to zero it may be best to do this over an average to avoid fast spikes in accelerometer
	               values affecting when the main loop is started. We will have to coordinate transform this into the NED frame
	               and I can work on getting this done ASAP unless we already have something we can use for this.
	               */
	   //EXAMPLE: MAIN INITIALIZATION - REPLACE NECESSARY ELEMENTS WITH SENSOR STRUCT FIELDS
	   //So for example, gps[3] takes in gga struct latitude, longitude, and altitude (or global struct)

	   //float gps[3] = {global_mission_data.GPS_LATITUDE, global_mission_data.GPS_LONGITUDE, global_mission_data.GPS_ALTITUDE};
	   //float accel[3][1] = {{global_mission_data.ACCEL_X},{global_mission_data.ACCEL_Y},{global_mission_data.ACCEL_Z}}; //acceleration from the accelerometer (g) (XYZ)
	   //float gyro[3][1] = {{global_mission_data.GYRO_R},{global_mission_data.GYRO_P},{global_mission_data.GYRO_Y}}; // Gyro (RPY)

	   //nav = init_Navigation(gps, accel, gyro); //initialize the navigation states

       if (cal_count == 1) {
		   nav = init_Navigation((float[3]){global_mission_data.GPS_LATITUDE, global_mission_data.GPS_LONGITUDE, global_mission_data.GPS_ALTITUDE},
				   (float[3][1]){{global_mission_data.ACCEL_X},{global_mission_data.ACCEL_Y},{global_mission_data.ACCEL_Z}},
				   (float[3][1]){{global_mission_data.GYRO_R},{global_mission_data.GYRO_P},{global_mission_data.GYRO_Y}});
       }
   }

    if (global_flags.mec_egg_release) {
    	SERVO_MoveTo_180(SERVO_Motor0, 0);
    }

//    RTC_TimeTypeDef sTime = {0};
//    // Needed to unlock time registers
//    RTC_DateTypeDef sDate = {0};
//
//    if (HAL_RTC_GetTime(&hrtc, &sTime, RTC_FORMAT_BIN) != HAL_OK)
//    {
//      Error_Handler();
//    }
//
//    // Needed to unlock time registers
//    if (HAL_RTC_GetDate(&hrtc, &sDate, RTC_FORMAT_BIN) != HAL_OK)
//    {
//      Error_Handler();
//    }

//	snprintf(global_mission_data.MISSION_TIME, 9, "XX:XX:XX");
//    snprintf(global_mission_data.MISSION_TIME, 9, "%02d:%02d:%02d",
//             sTime.Hours, sTime.Minutes, sTime.Seconds);

    /*
     * Get Voltage and Current from Magnetometer
     */

    /*
     * Get GPS information from GPS
     */

    // Relinquish access to the global_mission_data struct

//    SERVO_Sweep_180(SERVO_Motor0);

    osSemaphoreRelease(globalDataHandle);

    osDelay(100);
  }
  /* USER CODE END 5 */
}

void StartReadCommands(void const * argument)
{
  /* USER CODE BEGIN StartReadCommands */
	osStatus stat = osErrorOS;

	char rx_string[30];
    for (;;)
    {

        if (!COMMAND_READY) {
            osThreadYield();
            continue;
        }

        // The point of this loop is to find the start delimeter in the DMA buffer.
        // The DMA system will occasionally start with garbage data, this ensures
        //   that it doesn't drop a message for something as stupid as that.
        uint8_t offset = 0;
        for (; offset < 50; offset++) {
       		if (xbee_receive_buffer[offset] == 0x7E) {
        		break;
        	}
        }

        xbee_status_t status = xbee_decode_tx_request(&xbee_receive_buffer[offset], (COMMAND_SIZE-offset), &rx_string[0], sizeof(rx_string), NULL);
        if (status != XBEE_OK) {
            COMMAND_READY = 0;
            continue;
        }

        stat = osSemaphoreWait(globalDataHandle, 100);
        if (stat != osOK) {
            osThreadYield();
            continue; // Semaphore is either unavailable or inputs are wrong
        }
        // HAL_GPIO_TogglePin(DEBUG_0_GPIO_Port, DEBUG_0_Pin);

        if (strncmp(rx_string, "CMD,1075,CX,ON", 14) == 0)
        {
            // set command echo in the global mission struct
            char c_echo[] = "CXON";
            strcpy(global_mission_data.CMD_ECHO, c_echo);
            global_flags.telemetry_enable = 1;
        }
        // CX OFF command -> stop transmitting telemetry packets
        else if (strncmp(rx_string, "CMD,1075,CX,OFF", 15) == 0)
        {
            // set command echo
            char c_echo[] = "CXOFF";
            strcpy(global_mission_data.CMD_ECHO, c_echo);
            global_flags.telemetry_enable = 0;
        }
        // ST command -> set mission time
        else if (strncmp(rx_string, "CMD,1075,ST,", 12) == 0)
        {
            // parse the timestamp to set to
            char arg[9];
            char *time_str = rx_string + 12;
            strncpy(arg, time_str, 9);

            // removed this code because GPS is screwed
            // if a manual timestamp has been input...
            HAL_TICK_OFFSET = HAL_GetTick();
            if (strlen(arg) == 8)
            {
            	// set mission time
                char *str_end;
                strncpy(global_mission_data.MISSION_TIME, time_str, 9);
                string_to_time(&global_mission_data.MISSION_TIME[0], &global_mission_data.MISSION_TIME_ms);
            }
            // read time from GPS
            else if (strncmp(time_str, "GPS", 3) == 0)
            {
            	global_mission_data.MISSION_TIME_ms = rmc_data.time_ms;
            }
            else
            {
            // if the string is not 8 characters long, set it to "00:00:00"
            	strcpy(global_mission_data.MISSION_TIME, "00:00:00");
                string_to_time(&global_mission_data.MISSION_TIME[0], &global_mission_data.MISSION_TIME_ms);
            }

            // set command echo
            char c_echo[] = "ST";
            strcpy(global_mission_data.CMD_ECHO, c_echo);
        }
        // SIM ENABLE command -> allow simulation mode to be activated
        else if (strncmp(rx_string, "CMD,1075,SIM,ENABLE", 19) == 0)
        {
            // set command echo
            char c_echo[] = "SIMENABLE";
            strcpy(global_mission_data.CMD_ECHO, c_echo);
            global_flags.simulation_pre = 1;
        }
        // SIM ACTIVATE command -> turn simulation mode on
        else if (strncmp(rx_string, "CMD,1075,SIM,ACTIVATE", 21) == 0)
        {
            // check that simulation mode has been activated
            if (global_flags.simulation_pre == 1)
            {
                // make first simulated pressure value match actual value
                simulated_pressure = global_mission_data.PRESSURE;
                // set command echo
                char c_echo[] = "SIMACT";
                strcpy(global_mission_data.CMD_ECHO, c_echo);
                memcpy(&global_mission_data.MODE, "S", 1);
            }
            else{
            	char c_echo[] = "SIMACT_REJ";
                strcpy(global_mission_data.CMD_ECHO, c_echo);
            }
        }
        // SIM DISABLE command -> turn simulation mode off
        else if (strncmp(rx_string, "CMD,1075,SIM,DISABLE", 20) == 0)
        {
            // set command echo
            char c_echo[] = "SIMDIS";
            strcpy(global_mission_data.CMD_ECHO, c_echo);
            global_flags.simulation_pre = 0;
            memcpy(&global_mission_data.MODE, "F", 1);
        }
        // SIMP command -> add simulated pressure data
        else if (strncmp(rx_string, "CMD,1075,SIMP,", 14) == 0)
        {
            // parse inputed pressure data
            // char *pressure_str = rx_string + 14;
            // char *str_end;
        	simulated_pressure = atof(rx_string + 14) / 1000.0;
            // if (str_end == pressure_str || *str_end != '\0')
            // it wasn't a valid number
            // set simulated pressure to parsed value

            // set command echo
            char c_echo[] = "SIMP";
            strcpy(global_mission_data.CMD_ECHO, c_echo);
        }
        // CAL command -> calibrate altitude
        else if (strncmp(rx_string, "CMD,1075,CAL", 12) == 0)
        {
            // set command echo
            char c_echo[] = "CAL";
            char new_state[]= "LAUNCH_PAD";

            calibrating = 1;
            cal_sum = 0;
            cal_count = 0;

            strcpy(global_mission_data.STATE, new_state);
            strcpy(global_mission_data.CMD_ECHO, c_echo);
        }
        // MEC WIRE ON command -> actuate (servos?)
        else if (strncmp(rx_string, "CMD,1075,MEC,WIRE,ON", 20) == 0)
        {
        // activate MEC command
        }
        // MEC WIRE OFF command -> stop actuations
        else if (strncmp(rx_string, "CMD,1075,MEC,WIRE,OFF", 21) == 0)
        {
        // turn off MEC command (servos for GNC?)
        }
		// Servo #0
        else if (strncmp(rx_string, "CMD,1075,MEC,SERVO0,", 20) == 0)
		{
		  float angle = atof(rx_string + 20);
		  SERVO_MoveTo_180(SERVO_Motor0, angle);
		}
		// Servo #1
        else if (strncmp(rx_string, "CMD,1075,MEC,SERVO1,", 20) == 0)
		{
		  float angle = atof(rx_string + 20);
		  SERVO_MoveTo_180(SERVO_Motor1, angle);
		}
		// Servo #2
        else if (strncmp(rx_string, "CMD,1075,MEC,SERVO2,", 20) == 0)
		{
		  float angle = atof(rx_string + 20);
		  SERVO_MoveTo_180(SERVO_Motor2, angle);
		}
		// Servo #3
        else if (strncmp(rx_string, "CMD,1075,MEC,SERVO3,", 20) == 0)
		{
		  float angle = atof(rx_string + 20);
		  SERVO_MoveTo_180(SERVO_Motor3, angle);
		}
		// Servo #4
        else if (strncmp(rx_string, "CMD,1075,MEC,SERVO4,", 20) == 0)
		{
		  float angle = atof(rx_string + 20);
		  SERVO_MoveTo_180(SERVO_Motor4, angle);
		}
		// Servo #5
        else if (strncmp(rx_string, "CMD,1075,MEC,EGG,", 17) == 0)
		{
		  float angle = atof(rx_string + 17);
		  SERVO_MoveTo_180(EGG_SERVO, angle);
		}
        else if (strncmp(rx_string, "CMD,1075,MEC,RELEASE,", 21) == 0)
        {
        	uint8_t release_can = strncmp(rx_string+21, "ON", 2) ? 0 : 1; // If strncmp != 0, then assume "OFF"

        	// FIXME : If the servos become 270 degree servos these sets of functions will need to be swapped over.
        	if (release_can) {
        		SERVO_MoveTo_180(RELEASE_SERVO0, 0);
        		SERVO_MoveTo_180(RELEASE_SERVO1, 0);
        	} else {
        		SERVO_MoveTo_180(RELEASE_SERVO0, 90);
				SERVO_MoveTo_180(RELEASE_SERVO1, 90);
        	}
        }
        else if (strncmp(rx_string, "CMD,1075,MEC,GUIDANCE,", 22) == 0)
        {
        	uint8_t left_right = strncmp(rx_string+22, "LEFT", 4) ? 0 : 1;

        	if (left_right) {
        		SERVO_MoveTo_180(GUIDE_SERVO0, 0);
        		SERVO_MoveTo_180(GUIDE_SERVO1, 0);
        	} else {
        		SERVO_MoveTo_180(GUIDE_SERVO0, 90);
				SERVO_MoveTo_180(GUIDE_SERVO1, 90);
        	}
        }
        else if (strncmp(rx_string, "CMD,1075,GNC_ACT,", 17) == 0)
        {
        	nav.activateGNC = 1;
        }
        else if (strncmp(rx_string, "CMD,1075,MEC,CAM0,", 18) == 0)
        {
        	if (strncmp(rx_string+18, "ON", 2) == 0) {
        		HAL_GPIO_WritePin(CAM0_CTRL_GPIO_Port, CAM0_CTRL_Pin, GPIO_PIN_SET);
        }
        else {
        		HAL_GPIO_WritePin(CAM0_CTRL_GPIO_Port, CAM0_CTRL_Pin, GPIO_PIN_RESET);
        }

        }

        COMMAND_READY = 0;

        osSemaphoreRelease(globalDataHandle);

        // clear command buffer
        memset(rx_string, 0, sizeof(rx_string)); // Can someone double check if this is supposed to clear the command buffer?
        memset(xbee_receive_buffer, 0, sizeof(xbee_receive_buffer));
        osDelay(10);
    }
  /* USER CODE END StartReadCommands */
}

void StartSendTelemetry(void const * argument)
{
  /* USER CODE BEGIN StartSendTelemetry */
  osStatus stat = osErrorOS;
//  global_flags.telemetry_enable = 1;
  /* Infinite loop */
  for (;;) {
    // manually defines a critical region to ensure half-packets are never
    // transmitted
    //    taskENTER_CRITICAL();

    if (!global_flags.telemetry_enable) {
      osThreadYield();
      continue;
    }

    // create an empty buffer for the telemetry packet string
    char telemetry_string[200] = {0};

    // Generic temporary variable for use in sprintf() calls, etc.
    uint16_t str_len = 0;
    // Request semaphore access
    if (osSemaphoreWait(globalDataHandle, 100) != osOK) {
    	continue; // Until we can acquire a lock on the data, we do not want to read from it
    }

    HAL_GPIO_TogglePin(DEBUG_2_GPIO_Port, DEBUG_2_Pin);

    // fill the buffer with the first half of the packet
    str_len = sprintf(telemetry_string, "%d,%s,%ld,%c,%s,%3.2f,%.2f,%.3f,%.2f,%.2f,%.2f,%.2f,%.2f,%.2f,%.2f,%.2f,%s,%.4f,%.4f,%.4f,%d,%s",
                      global_mission_data.TEAM_ID,      // team id (1075)
                      global_mission_data.MISSION_TIME, // mission time
                      global_mission_data.PACKET_COUNT, // packet count
                      global_mission_data.MODE,         // mode
                      global_mission_data.STATE,        // state
                      global_mission_data.ALTITUDE,     // calibrated altitude (m)
                      global_mission_data.TEMPERATURE,  // temperature (C)
                      global_mission_data.PRESSURE,     // pressure (kPa)
                      global_mission_data.VOLTAGE,      // battery voltage (V)
					  global_mission_data.CURRENT,
                      global_mission_data.GYRO_R,       // gyro roll (degrees/s)
                      global_mission_data.GYRO_P,       // gyro pitch (degrees/s)
                      global_mission_data.GYRO_Y,        // gyro yaw (degrees/s)
                      global_mission_data.ACCEL_R,                 // accelerometer roll (degrees/s^2)
                      global_mission_data.ACCEL_P,                 // accelerometer pitch (degrees/s^2)
                      global_mission_data.ACCEL_YAW,                 // accelerometer yaw (degrees/s^2)
                      global_mission_data.GPS_TIME,                // GPS time
                      global_mission_data.GPS_ALTITUDE,            // GPS (absolute) altitude (m)
                      global_mission_data.GPS_LATITUDE,            // GPS latitude
                      global_mission_data.GPS_LONGITUDE,           // GPS longitude
                      global_mission_data.GPS_SATS,                // # of connected GPS satellites
                      global_mission_data.CMD_ECHO                 // tracks previously received command
    );

    char frame[200] = {0};
    uint16_t data_len = 0;
    xbee_status_t status = xbee_send_api_packet(&telemetry_string[0], str_len, &frame[0], sizeof(frame), &data_len);
    if (status != XBEE_OK) {
    	osSemaphoreRelease(globalDataHandle);
    	continue;

    }
	HAL_UART_Transmit(&huart3, frame, data_len, HAL_MAX_DELAY);
//    HAL_UART_Transmit(&huart3, telemetry_string, str_len, HAL_MAX_DELAY);

//	uint32_t bytes_written = write_SD(&telemetry_string[0], str_len, "log26.csv", 0);

    // increment packet count once the entire packet has been transmitted
    global_mission_data.PACKET_COUNT = global_mission_data.PACKET_COUNT + 1;

    uint32_t bytes_written = write_SD(telemetry_string, str_len, "log26.csv", 0);

    // Convert ms to hh:mm:ss and put into MISSION_TIME
    time_to_string(global_mission_data.MISSION_TIME_ms + HAL_GetTick() - HAL_TICK_OFFSET, &global_mission_data.MISSION_TIME[0]);
    // Copy MISSION_TIMEs
    strcpy(&global_config.MISSION_TIME[0], &global_mission_data.MISSION_TIME[0]);
    // Save information to sd.
    save_config_to_sd();

    osSemaphoreRelease(globalDataHandle);
    // exit the critical region once both packets have been sent
    //    taskEXIT_CRITICAL();
    HAL_GPIO_TogglePin(USR_LED_GPIO_Port, USR_LED_Pin);
    HAL_GPIO_TogglePin(DEBUG_2_GPIO_Port, DEBUG_2_Pin);

//    SERVO_Sweep_180(SERVO_Motor2);

    osDelay(1000);
  }
  /* USER CODE END StartSendTelemetry */
}

void StartGNC(void const * argument)
{
  /* USER CODE BEGIN StartGNC */

  /* Infinite loop */
  for (;;) {

	// Not apart of Tristen's code.
    if (GPS_READY) {
      GPS_READY = 0;
    }

    if (nav.activateGNC) {
    	if(CALIBRATE_HEAD_NEEDED){
			nav.rpy[2][0] = atan2f(pstmpv_data.vel_East, pstmpv_data.vel_North);
			CALIBRATE_HEAD_NEEDED = 0;
    	}
		// Tristan's GNC Code
		Update_Navigation(&nav, (float[3]){global_mission_data.GPS_LATITUDE, global_mission_data.GPS_LONGITUDE, global_mission_data.GPS_ALTITUDE},
					   (float[3][1]){{global_mission_data.GYRO_R},{global_mission_data.GYRO_P},{global_mission_data.GYRO_Y}},
					   (float[3][1]){{global_mission_data.ACCEL_X},{global_mission_data.ACCEL_Y},{global_mission_data.ACCEL_Z}},
					   (float[3][1]){{pstmpv_data.vel_North},{pstmpv_data.vel_East},{pstmpv_data.vel_Vert}});
		Update_Guidance(&nav,&guid); 				// With the new navigation states, update guidance commands
		Update_Autopilot(&guid,&nav,&ap); 			// Determine autopilot commands which convert guidance commands into rotations
		float cmd = computeCommand(&nav,&ap); 	// Compute the rotations necessary to turn the motors in us

		// SERVE CODE // (the servos should be run at a 50Hz frequency.)
		// TODO: This should be tested.
		SERVO_RawMove(GUIDE_SERVO0, cmd);
//		SERVO_Sweep_180(GUIDE_SERVO0);
		SERVO_RawMove(GUIDE_SERVO1, cmd);

		//CONDITIONAL LOGIC (this mainly just checks whether the paraglider needs to search for a target)
		if (nav.slack == 1 && nav.DROPNOW == 1) {
			printf("Condition 1 Entered. Deploying Egg....\n");
			//ADD DEPLOYMENT CODE HERE (write to release servo)
			SERVO_RawMove(EGG_SERVO, SERVO_Get_MaxPulse(EGG_SERVO));
		}
		else if (nav.slack == 1 && nav.DROPNOW == 0) {
			printf("Condition 2 Entered. Searching for nearest target...\n");
			findTarget(&nav, (float[3]){global_mission_data.GPS_LATITUDE, global_mission_data.GPS_LONGITUDE, global_mission_data.GPS_ALTITUDE});
		}
		else if (nav.slack == 0 && nav.DROPNOW == 1) {
			printf("Condition 3. Deploying Egg....\n");
			//ADD DEPLOYMENT CODE HERE (write to release servo)
			SERVO_RawMove(EGG_SERVO, SERVO_Get_MaxPulse(EGG_SERVO));
		}
		else if (nav.slack == 0 && nav.DROPNOW == 0) {
			printf("Condition 4 Entered, Glider in Coast Phase\n");
			findTarget(&nav, (float[3]){global_mission_data.GPS_LATITUDE, global_mission_data.GPS_LONGITUDE, global_mission_data.GPS_ALTITUDE});
		}
    }

    HAL_GPIO_TogglePin(DEBUG_0_GPIO_Port, DEBUG_0_Pin);
    osThreadYield();
  }
  /* USER CODE END StartGNC */
}

void StartInit(void const * argument)
{
  /* USER CODE BEGIN StartInit */
  init_SD();

  if (global_micro_sd_data.successfullyMounted) {
    uint32_t result = load_config_from_sd();
    if (result != APP_OK) {
      HAL_GPIO_WritePin(DEBUG_0_GPIO_Port, DEBUG_0_Pin, GPIO_PIN_SET);
      // Set default config
      set_default_config();
      save_config_to_sd();
    }
  } else {
//    HAL_GPIO_WritePin(DEBUG_0_GPIO_Port, DEBUG_0_Pin, GPIO_PIN_SET);
    set_default_config();
  }

  // Read Config file and update accordingly
  global_mission_data.ALTITUDE_OFFSET = global_config.ALTITUDE_OFFSET;
  global_mission_data.PACKET_COUNT = global_config.PACKET_COUNT;

  strcpy(global_mission_data.MISSION_TIME, global_config.MISSION_TIME);
  strcpy(global_mission_data.STATE, global_config.STATE);

  // This lets you see the minimum amount of the stack was remaining at any
  // time
  //  during a thread's execution.
  UBaseType_t stackHighWaterMark = uxTaskGetStackHighWaterMark(NULL);

//  HAL_GPIO_WritePin(DEBUG_1_GPIO_Port, DEBUG_1_Pin, GPIO_PIN_SET);

  SERVO_Init(SERVO_Motor0, &htim2);
  SERVO_MoveTo_180(SERVO_Motor0, 0);
  SERVO_Init(SERVO_Motor1, &htim3);
  SERVO_MoveTo_180(SERVO_Motor1, 0);
  SERVO_Init(SERVO_Motor2, &htim3);
  SERVO_MoveTo_180(SERVO_Motor2, 0);
  SERVO_Init(SERVO_Motor3, &htim3);
  SERVO_MoveTo_180(SERVO_Motor3, 0);
  SERVO_Init(SERVO_Motor4, &htim3);
  SERVO_MoveTo_180(SERVO_Motor4, 0);

  HAL_GPIO_WritePin(DEBUG_2_GPIO_Port, DEBUG_2_Pin, GPIO_PIN_SET);

  // Init task has nothing left to do — delete itself
  //	osThreadTerminate(osThreadGetId());
  vTaskDelete(NULL);

  for (;;)
    ;

  /* USER CODE END StartInit */
}

void HAL_TIM_PeriodElapsedCallback(TIM_HandleTypeDef *htim)
{
  if (htim->Instance == TIM6)
  {
    HAL_IncTick();
  }
}

void Error_Handler(void)
{
  __disable_irq();
  while (1)
  {
  }
}
